# psoc4200bl register map
Vendor: Cypress Semiconductor; Series: PSoC4200BL; File version: 1.0
CPU: CM0 r0p1, little endian, no MPU, no FPU, 2 interrupt priority bits
Registers are 32-bit, read-write, reset 0x0 unless marked. A register's access mark holds for its fields unless they carry their own. Offsets are from the block's base; [hi:lo] are bit positions.

## TST — Test Subsystem
Base 0x40030000
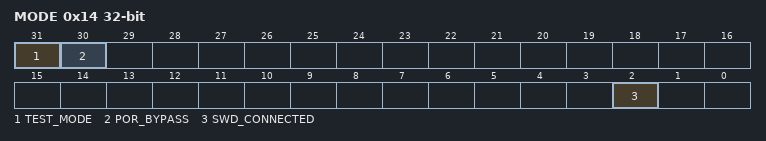
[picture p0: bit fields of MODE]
0x14 MODE — Test Mode Control Register
  [31] TEST_MODE — 0: Normal operation mode 1: Test mode (any test mode) Setting this bit will prevent BootROM from yielding execution to Flash image.
  [30] POR_BYPASS ro — This bit is set during POR bypass mode. When this bit is set, the BootROM will not yield execution to the FLASH image (same function as setting TEST_MODE bit below).
  [2] SWD_CONNECTED ro — 0: SWD not active 1: SWD activated (Line Reset & Connect sequence passed) (Note: this bit replaces TST_CTRL.SWD_CONNECTED and is present in all M0S8 products except TSG4)

## SPCIF — Flash Control Interface
Base 0x40110000
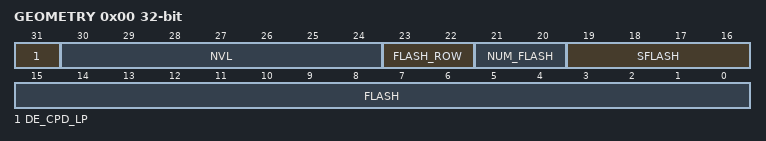
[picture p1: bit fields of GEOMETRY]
0x00 GEOMETRY (reset mask 0x80000000) — Flash/NVL geometry information
  [31] DE_CPD_LP — 0': SRAM busy wait loop has not been copied. '1': Busy wait loop has been written into SRAM.
  [30:24] NVL ro — NVLatch size in Byte multiples (chip dependent): '0': 0 Bytes '1': 1 Byte ... '127': 127 Bytes
  [23:22] FLASH_ROW ro — Page size in 64 Byte multiples (chip dependent): '0': 64 byte '1': 128 byte '2': 192 byte '3': 256 byte The page size is used to detemine the number of Bytes in a page for Flash page based operations (e.g. PGM_PAGE). Note: the field name FLASH_ROW is misleading, as this field specifies the number of Bytes in a page, rather than the number of Bytes in a row. In a single plane flash macro architecture, a page consists of a single row. However, in a multi plane flash macro architecture, a page consists of multiple rows from different planes.
  [21:20] NUM_FLASH ro — Number of flash macros (chip dependent): '0': 1 flash macro '1': 2 flash macros '2': 3 flash macros '3': 4 flash macros
  [19:16] SFLASH ro — Supervisory flash capacity in 256 Byte multiples (chip dependent). If multiple flash macros are present, this field provides the supervisory flash capacity of all flash macros together: '0': 256 Bytes. '1': 2*256 Bytes. ... '15': 16*256 Bytes.
  [15:0] FLASH ro — Regular flash capacity in 256 Byte multiples (chip dependent). If multiple flash macros are present, this field provides the flash capacity of all flash macros together: '0': 256 Bytes. '1': 2*256 Bytes. ... '65535': 65536*256 Bytes.
0x1C NVL_WR_DATA — NVL write data register
  [7:0] DATA — Data to be written to NVLatch array
0x7F0 INTR — SPCIF interrupt request register
  [0] TIMER — Timer counter value reaches '0'. Set to '1', when event is detected. Write INTR field with '1', to clear bit. Write INTR_SET field with '1', to set bit.
0x7F4 INTR_SET — SPCIF interrupt set request register
  [0] TIMER — Write INTR_SET field with '1' to set corresponding INTR field.
0x7F8 INTR_MASK — SPCIF interrupt mask register
  [0] TIMER — Mask for corresponding field in INTR register.
0x7FC INTR_MASKED ro — SPCIF interrupt masked request register
  [0] TIMER — Logical and of corresponding request and mask fields.

## CSD0 — Capsense Controller
Base 0x40280000
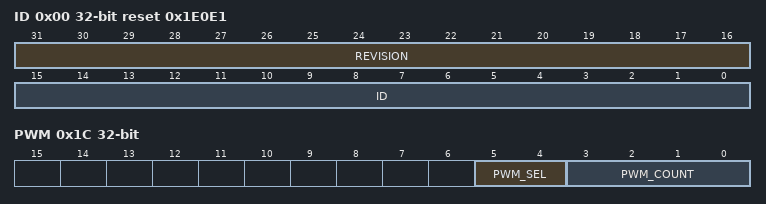
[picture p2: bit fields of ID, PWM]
0x00 ID ro reset 0x1E0E1 — ID & Revision Number
  [31:16] REVISION — the version number is 0x0001
  [15:0] ID — the ID of CSD peripheral is 0xE0E1
0x14 INTR — CSD Interrupt Request Register
  [0] CSD — The CSD IRQ bit is set. Firmware must clear this bit as part of the interrupt handler.
0x18 INTR_SET — CSD Interrupt set register
  [0] CSD — Write with '1' to set corresponding bit in interrupt request register.
0x1C PWM — CSD PWM Register
  [5:4] PWM_SEL — The mode of the PWM modulator
    0=OFF (The PWM modulator is OFF and has no effect); 2=FIXED_HIGH (The PWM modulator changes the low phase of csd_sense to a fixed length (used for negative charge transfer).); 3=FIXED_LOW (The PWM modulator changes the high phase of csd_sense to a fixed length (used for positive charge transfer).)
  [3:0] PWM_COUNT — The length of the modulation pulse in clk_csd2 cycles.
